AUTOSAR XML (schema 00045)
package /RtaAdapter
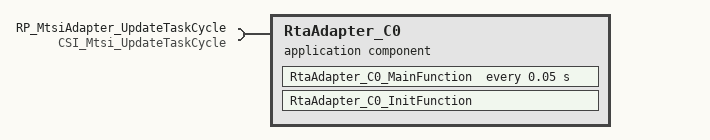
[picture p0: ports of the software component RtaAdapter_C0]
  application sw component type RtaAdapter_C0
    require port RP_MtsiAdapter_UpdateTaskCycle: required-interface=CSI_Mtsi_UpdateTaskCycle
    behavior RtaAdapter_C0_IB: handle-termination-and-restart=NO-SUPPORT
      init event InitEvent_RtaAdapter_C0: start-on-event=RtaAdapter_C0_InitFunction
      timing event TimingEvent_RtaAdapter_C0: start-on-event=RtaAdapter_C0_MainFunction, period=0.05
      runnable RtaAdapter_C0_InitFunction
      runnable RtaAdapter_C0_MainFunction
        sync call scp_UpdateTaskCycle: operation=RP_MtsiAdapter_UpdateTaskCycle.UpdateTaskCycle, timeout=0.0
  swc implementation RtaAdapter_C0_Impl: programming-language=C, sw-version=1.0.0, vendor-id=0, behavior=RtaAdapter_C0_IB
    code-descriptors:
      code CodeGen: artifact-descriptors=[{short-label=SWHDR, category=SWHDR}, {short-label=SWSRC, category=SWSRC}]
    resource consumption Resource
      memory section CODE: sw-addrmethod=CODE
      memory section VAR_UNSPECIFIED: sw-addrmethod=VAR
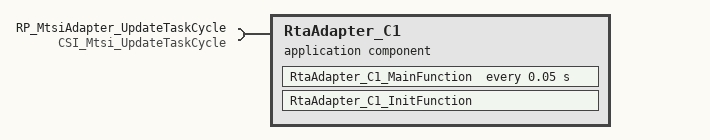
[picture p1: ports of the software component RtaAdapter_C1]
  application sw component type RtaAdapter_C1
    require port RP_MtsiAdapter_UpdateTaskCycle: required-interface=CSI_Mtsi_UpdateTaskCycle
    behavior RtaAdapter_C1_IB: handle-termination-and-restart=NO-SUPPORT
      init event InitEvent_RtaAdapter_C1: start-on-event=RtaAdapter_C1_InitFunction
      timing event TimingEvent_RtaAdapter_C1: start-on-event=RtaAdapter_C1_MainFunction, period=0.05
      runnable RtaAdapter_C1_InitFunction
      runnable RtaAdapter_C1_MainFunction
        sync call scp_UpdateTaskCycle: operation=RP_MtsiAdapter_UpdateTaskCycle.UpdateTaskCycle, timeout=0.0
  swc implementation RtaAdapter_C1_Impl: programming-language=C, sw-version=1.0.0, vendor-id=0, behavior=RtaAdapter_C1_IB
    code-descriptors:
      code CodeGen: artifact-descriptors=[{short-label=SWHDR, category=SWHDR}, {short-label=SWSRC, category=SWSRC}]
    resource consumption Resource
      memory section CODE: sw-addrmethod=CODE
      memory section VAR_UNSPECIFIED: sw-addrmethod=VAR
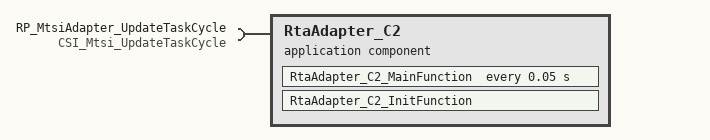
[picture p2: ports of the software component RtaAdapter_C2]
  application sw component type RtaAdapter_C2
    require port RP_MtsiAdapter_UpdateTaskCycle: required-interface=CSI_Mtsi_UpdateTaskCycle
    behavior RtaAdapter_C2_IB: handle-termination-and-restart=NO-SUPPORT
      init event InitEvent_RtaAdapter_C2: start-on-event=RtaAdapter_C2_InitFunction
      timing event TimingEvent_RtaAdapter_C2: start-on-event=RtaAdapter_C2_MainFunction, period=0.05
      runnable RtaAdapter_C2_InitFunction
      runnable RtaAdapter_C2_MainFunction
        sync call scp_UpdateTaskCycle: operation=RP_MtsiAdapter_UpdateTaskCycle.UpdateTaskCycle, timeout=0.0
  swc implementation RtaAdapter_C2_Impl: programming-language=C, sw-version=1.0.0, vendor-id=0, behavior=RtaAdapter_C2_IB
    code-descriptors:
      code CodeGen: artifact-descriptors=[{short-label=SWHDR, category=SWHDR}, {short-label=SWSRC, category=SWSRC}]
    resource consumption Resource
      memory section CODE: sw-addrmethod=CODE
      memory section VAR_UNSPECIFIED: sw-addrmethod=VAR
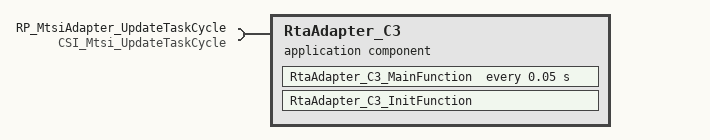
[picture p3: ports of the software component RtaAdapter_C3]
  application sw component type RtaAdapter_C3
    require port RP_MtsiAdapter_UpdateTaskCycle: required-interface=CSI_Mtsi_UpdateTaskCycle
    behavior RtaAdapter_C3_IB: handle-termination-and-restart=NO-SUPPORT
      init event InitEvent_RtaAdapter_C3: start-on-event=RtaAdapter_C3_InitFunction
      timing event TimingEvent_RtaAdapter_C3: start-on-event=RtaAdapter_C3_MainFunction, period=0.05
      runnable RtaAdapter_C3_InitFunction
      runnable RtaAdapter_C3_MainFunction
        sync call scp_UpdateTaskCycle: operation=RP_MtsiAdapter_UpdateTaskCycle.UpdateTaskCycle, timeout=0.0
  swc implementation RtaAdapter_C3_Impl: programming-language=C, sw-version=1.0.0, vendor-id=0, behavior=RtaAdapter_C3_IB
    code-descriptors:
      code CodeGen: artifact-descriptors=[{short-label=SWHDR, category=SWHDR}, {short-label=SWSRC, category=SWSRC}]
    resource consumption Resource
      memory section CODE: sw-addrmethod=CODE
      memory section VAR_UNSPECIFIED: sw-addrmethod=VAR
